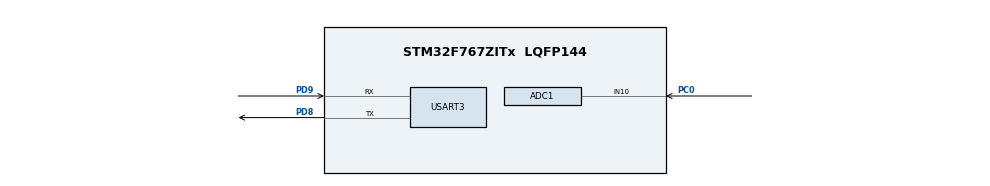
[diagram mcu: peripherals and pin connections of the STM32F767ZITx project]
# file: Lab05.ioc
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ADC1.Channel-0\#ChannelRegularConversion=ADC_CHANNEL_10
ADC1.ContinuousConvMode=ENABLE
ADC1.EOCSelection=ADC_EOC_SEQ_CONV
ADC1.NbrOfConversionFlag=1
ADC1.Rank-0\#ChannelRegularConversion=1
ADC1.SamplingTime-0\#ChannelRegularConversion=ADC_SAMPLETIME_3CYCLES
ADC1.master=1
Mcu.Family=STM32F7
Mcu.Name=STM32F767ZITx
Mcu.Package=LQFP144
NVIC.PriorityGroup=NVIC_PRIORITYGROUP_4
PC0.Signal=ADCx_IN10
PD8.Mode=Asynchronous
PD8.Signal=USART3_TX
PD9.Mode=Asynchronous
PD9.Signal=USART3_RX
ProjectManager.HeapSize=0x200
ProjectManager.StackSize=0x400
ProjectManager.TargetToolchain=STM32CubeIDE
RCC.HSE_VALUE=25000000
RCC.HSI_VALUE=16000000
RCC.LSE_VALUE=32768
RCC.USBFreq_Value=96000000
RCC.VCOOutputFreq_Value=192000000
SH.ADCx_IN10.0=ADC1_IN10,IN10
USART3.VirtualMode-Asynchronous=VM_ASYNC
board=custom

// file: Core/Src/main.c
/* USER CODE BEGIN Header */
/**
  ******************************************************************************
  * @file           : main.c
  * @brief          : Main program body
  ******************************************************************************
  * @attention
  *
  * Copyright (c) 2022 STMicroelectronics.
  * All rights reserved.
  *
  * This software is licensed under terms that can be found in the LICENSE file
  * in the root directory of this software component.
  * If no LICENSE file comes with this software, it is provided AS-IS.
  *
  ******************************************************************************
  */
/* USER CODE END Header */
#include "main.h"

/* USER CODE BEGIN Includes */
#include "stdio.h"
#include "string.h"
/* USER CODE END Includes */

ADC_HandleTypeDef hadc1;

UART_HandleTypeDef huart3;

/* USER CODE BEGIN PV */
volatile uint32_t adc_val = 0;
volatile uint32_t adc_avg_8 = 0;
volatile uint32_t adc_avg_16 = 0;
/* USER CODE END PV */

void SystemClock_Config(void);
static void MX_GPIO_Init(void);
static void MX_USART3_UART_Init(void);
static void MX_ADC1_Init(void);
/* USER CODE BEGIN PFP */
void displayHEX(uint32_t);
/* USER CODE END PFP */

int main(void)
{

  /* MCU Configuration--------------------------------------------------------*/

  /* Reset of all peripherals, Initializes the Flash interface and the Systick. */
  HAL_Init();

  /* Configure the system clock */
  SystemClock_Config();

  /* Initialize all configured peripherals */
  MX_GPIO_Init();
  MX_USART3_UART_Init();
  MX_ADC1_Init();
  /* USER CODE BEGIN 2 */
  HAL_ADC_Start(&hadc1);
  /* USER CODE END 2 */

  /* Infinite loop */
  while (1)
  {

    /* USER CODE BEGIN 3 */

	  while (HAL_ADC_PollForConversion(&hadc1, 100) != HAL_OK){}
	  adc_val = HAL_ADC_GetValue(&hadc1);
	  adc_avg_8 = average_8(adc_val);
	  adc_avg_16 = average_16(adc_val);
	  displayHEX(adc_val);
	  HAL_Delay(400);
  }
  /* USER CODE END 3 */
}

void SystemClock_Config(void)
{
  RCC_OscInitTypeDef RCC_OscInitStruct = {0};
  RCC_ClkInitTypeDef RCC_ClkInitStruct = {0};

  /** Configure the main internal regulator output voltage
  */
  __HAL_RCC_PWR_CLK_ENABLE();
  __HAL_PWR_VOLTAGESCALING_CONFIG(PWR_REGULATOR_VOLTAGE_SCALE3);

  /** Initializes the RCC Oscillators according to the specified parameters
  * in the RCC_OscInitTypeDef structure.
  */
  RCC_OscInitStruct.OscillatorType = RCC_OSCILLATORTYPE_HSI;
  RCC_OscInitStruct.HSIState = RCC_HSI_ON;
  RCC_OscInitStruct.HSICalibrationValue = RCC_HSICALIBRATION_DEFAULT;
  RCC_OscInitStruct.PLL.PLLState = RCC_PLL_NONE;
  if (HAL_RCC_OscConfig(&RCC_OscInitStruct) != HAL_OK)
  {
    Error_Handler();
  }

  /** Initializes the CPU, AHB and APB buses clocks
  */
  RCC_ClkInitStruct.ClockType = RCC_CLOCKTYPE_HCLK|RCC_CLOCKTYPE_SYSCLK
                              |RCC_CLOCKTYPE_PCLK1|RCC_CLOCKTYPE_PCLK2;
  RCC_ClkInitStruct.SYSCLKSource = RCC_SYSCLKSOURCE_HSI;
  RCC_ClkInitStruct.AHBCLKDivider = RCC_SYSCLK_DIV1;
  RCC_ClkInitStruct.APB1CLKDivider = RCC_HCLK_DIV1;
  RCC_ClkInitStruct.APB2CLKDivider = RCC_HCLK_DIV1;

  if (HAL_RCC_ClockConfig(&RCC_ClkInitStruct, FLASH_LATENCY_0) != HAL_OK)
  {
    Error_Handler();
  }
}

static void MX_ADC1_Init(void)
{

  ADC_ChannelConfTypeDef sConfig = {0};

  /** Configure the global features of the ADC (Clock, Resolution, Data Alignment and number of conversion)
  */
  hadc1.Instance = ADC1;
  hadc1.Init.ClockPrescaler = ADC_CLOCK_SYNC_PCLK_DIV2;
  hadc1.Init.Resolution = ADC_RESOLUTION_12B;
  hadc1.Init.ScanConvMode = ADC_SCAN_DISABLE;
  hadc1.Init.ContinuousConvMode = ENABLE;
  hadc1.Init.DiscontinuousConvMode = DISABLE;
  hadc1.Init.ExternalTrigConvEdge = ADC_EXTERNALTRIGCONVEDGE_NONE;
  hadc1.Init.ExternalTrigConv = ADC_SOFTWARE_START;
  hadc1.Init.DataAlign = ADC_DATAALIGN_RIGHT;
  hadc1.Init.NbrOfConversion = 1;
  hadc1.Init.DMAContinuousRequests = DISABLE;
  hadc1.Init.EOCSelection = ADC_EOC_SEQ_CONV;
  if (HAL_ADC_Init(&hadc1) != HAL_OK)
  {
    Error_Handler();
  }

  /** Configure for the selected ADC regular channel its corresponding rank in the sequencer and its sample time.
  */
  sConfig.Channel = ADC_CHANNEL_10;
  sConfig.Rank = ADC_REGULAR_RANK_1;
  sConfig.SamplingTime = ADC_SAMPLETIME_3CYCLES;
  if (HAL_ADC_ConfigChannel(&hadc1, &sConfig) != HAL_OK)
  {
    Error_Handler();
  }

}

static void MX_USART3_UART_Init(void)
{

  huart3.Instance = USART3;
  huart3.Init.BaudRate = 115200;
  huart3.Init.WordLength = UART_WORDLENGTH_8B;
  huart3.Init.StopBits = UART_STOPBITS_1;
  huart3.Init.Parity = UART_PARITY_NONE;
  huart3.Init.Mode = UART_MODE_TX_RX;
  huart3.Init.HwFlowCtl = UART_HWCONTROL_NONE;
  huart3.Init.OverSampling = UART_OVERSAMPLING_16;
  huart3.Init.OneBitSampling = UART_ONE_BIT_SAMPLE_DISABLE;
  huart3.AdvancedInit.AdvFeatureInit = UART_ADVFEATURE_NO_INIT;
  if (HAL_UART_Init(&huart3) != HAL_OK)
  {
    Error_Handler();
  }

}

static void MX_GPIO_Init(void)
{

  /* GPIO Ports Clock Enable */
  __HAL_RCC_GPIOC_CLK_ENABLE();
  __HAL_RCC_GPIOD_CLK_ENABLE();

}

/* USER CODE BEGIN 4 */
void displayHEX(uint32_t hex1)
{
	char str[32];

	sprintf(str,"ADC1_CH10 0x%08X Vin = %.2f V\n\r",hex1,(float)hex1/4096.0*3.3);
	while(__HAL_UART_GET_FLAG(&huart3,UART_FLAG_TC)==RESET){}
	HAL_UART_Transmit(&huart3, (uint8_t*) str, strlen(str),1000);

}
int average_8(int x)
{
	static int samples[8];
	static int i = 0;
	static int total = 0;

	total += x - samples[i];
	samples[i] = x;

	i = (i==7 ? 0 : i+1);

	return total>>3;
}
int average_16(int x) {
	static int samples[16];
	static int i = 0;
	static int total = 0;

	total += x - samples[i];
	samples[i] = x;

	i = (i==15 ? 0 : i+1);

	return total>>4;
}
/* USER CODE END 4 */

void Error_Handler(void)
{
  __disable_irq();
  while (1)
  {
  }
}
